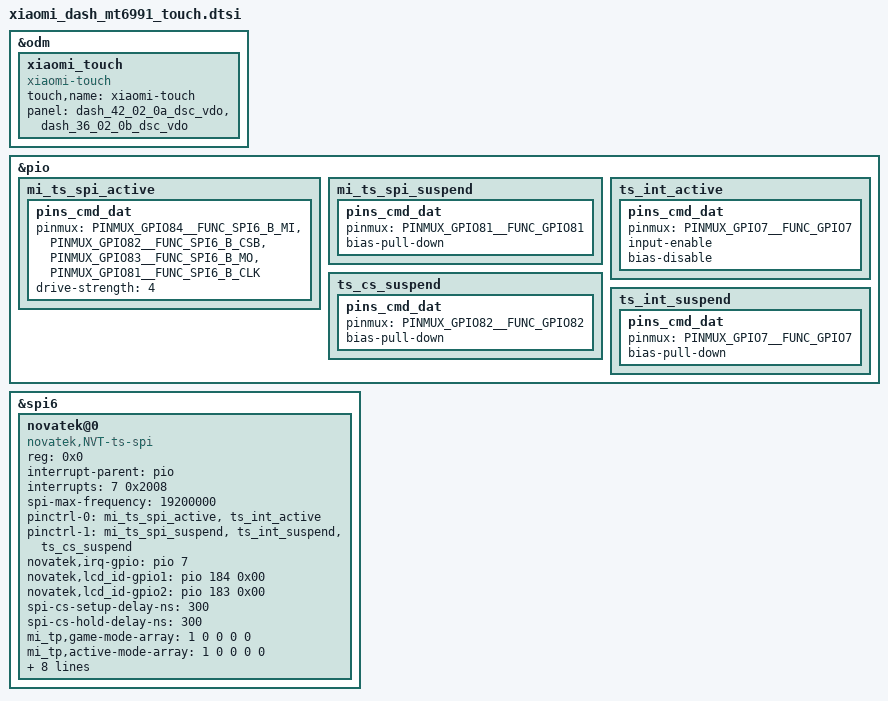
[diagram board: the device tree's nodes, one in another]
// SPDX-License-Identifier: (GPL-2.0 OR MIT)
/*
 * Copyright (C) 2020 MediaTek Inc.
 */

/* TOUCH start */
&odm {
	xiaomi_touch: xiaomi_touch {
		compatible = "xiaomi-touch";
		status = "ok";
		touch,name = "xiaomi-touch";
		panel = <&dash_42_02_0a_dsc_vdo
		&dash_36_02_0b_dsc_vdo>;
	};
};

&pio {
	mi_ts_spi_active: mi_ts_spi_active {
		pins_cmd_dat {
			pinmux = <PINMUX_GPIO84__FUNC_SPI6_B_MI>,
					<PINMUX_GPIO82__FUNC_SPI6_B_CSB>,
					<PINMUX_GPIO83__FUNC_SPI6_B_MO>,
					<PINMUX_GPIO81__FUNC_SPI6_B_CLK>;
			drive-strength = <4>;
		};
	};
	mi_ts_spi_suspend: mi_ts_spi_suspend {
		pins_cmd_dat {
			pinmux = <PINMUX_GPIO81__FUNC_GPIO81>;
			bias-pull-down;
		};
	};
	ts_int_active: ts_int_active {
		pins_cmd_dat {
			pinmux = <PINMUX_GPIO7__FUNC_GPIO7>;
			input-enable;
			bias-disable;
		};
	};
	ts_cs_suspend:ts_cs_suspend {
		pins_cmd_dat{
			pinmux = <PINMUX_GPIO82__FUNC_GPIO82>;
			bias-pull-down;
		};
	};
	ts_int_suspend: ts_int_suspend {
		pins_cmd_dat {
			pinmux = <PINMUX_GPIO7__FUNC_GPIO7>;
			bias-pull-down;
		};
	};
};

&spi6 {
	status = "ok";

	/* Novatek device tree node */
	novatek@0 {
		compatible = "novatek,NVT-ts-spi";
		reg = <0x0>;
		status = "ok";
		interrupt-parent = <&pio>;
		interrupts = <7 0x2008>;
		spi-max-frequency = <19200000>;	//4800000,9600000,15000000,19200000
		pinctrl-names = "pmx_ts_active", "pmx_ts_suspend";
		pinctrl-0 = <&mi_ts_spi_active &ts_int_active>;
		pinctrl-1 = <&mi_ts_spi_suspend &ts_int_suspend &ts_cs_suspend>;

		/* novatek dtsi start */
		novatek,irq-gpio = <&pio 7 0x2008>;
		novatek,lcd_id-gpio1 = <&pio 184 0x00>;
		novatek,lcd_id-gpio2 = <&pio 183 0x00>;
		spi-cs-setup-delay-ns = <300>;
		spi-cs-hold-delay-ns = <300>;

		/* xiaomi touch default param */
		mi_tp,game-mode-array =
						<1 0 0 0 0>;  /* MAX MIN DEF SET GET */
		mi_tp,active-mode-array =
						<1 0 0 0 0>;  /* MAX MIN DEF SET GET */
		mi_tp,tolerance-array =
						<4 0 2 2 2>;  /* MAX MIN DEF SET GET */
		mi_tp,up-threshold-array =
						<4 0 3 3 3>;  /* MAX MIN DEF SET GET */
		mi_tp,aim-sensitivity-array =
						<4 0 2 2 2>;  /* MAX MIN DEF SET GET */
		mi_tp,tap-stability-array =
						<4 0 2 2 2>;  /* MAX MIN DEF SET GET */
		mi_tp,edge-filter-array =
						<3 0 2 2 2>;  /* MAX MIN DEF SET GET */
		mi_tp,panel-orien-array =
						<3 0 0 0 0>;  /* MAX MIN DEF SET GET */
		mi_tp,report-rate-array =
						<3 0 0 0 0>;  /* MAX MIN DEF SET GET */
		mi_tp,expert-mode-array =
						<3 1 1 1 1>;  /* MAX MIN DEF SET GET */
		/* novatek dtsi end */
	};
};

/* TOUCH end */
